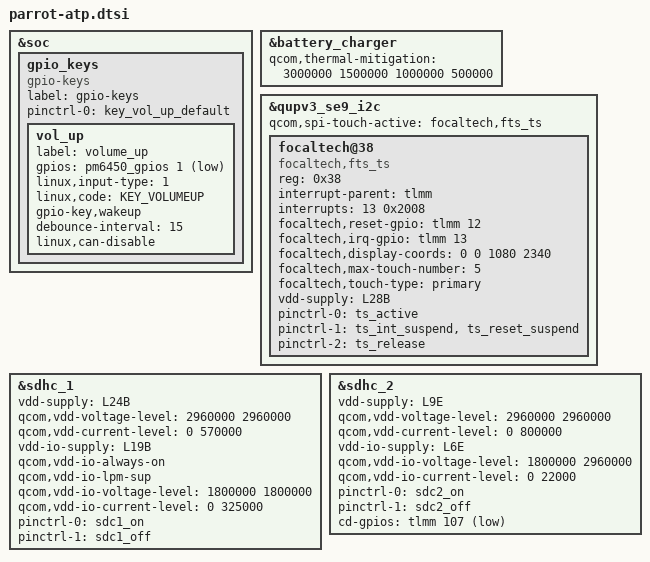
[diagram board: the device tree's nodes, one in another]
#include <dt-bindings/gpio/gpio.h>
#include <dt-bindings/input/input.h>

#include "parrot-pm7250b.dtsi"
#include "parrot-pmic-overlay.dtsi"
#include "parrot-thermal-overlay.dtsi"

&soc {
	gpio_keys {
		compatible = "gpio-keys";
		label = "gpio-keys";

		pinctrl-names = "default";
		pinctrl-0 = <&key_vol_up_default>;

		vol_up {
			label = "volume_up";
			gpios = <&pm6450_gpios 1 GPIO_ACTIVE_LOW>;
			linux,input-type = <1>;
			linux,code = <KEY_VOLUMEUP>;
			gpio-key,wakeup;
			debounce-interval = <15>;
			linux,can-disable;
		};
	};
};

&battery_charger {
	qcom,thermal-mitigation = <3000000 1500000 1000000 500000>;
};

&qupv3_se9_i2c {
	#address-cells = <1>;
	#size-cells = <0>;

	status = "ok";
	qcom,spi-touch-active = "focaltech,fts_ts";

	focaltech@38 {
		compatible = "focaltech,fts_ts";
		reg = <0x38>;
		interrupt-parent = <&tlmm>;
		interrupts = <13 0x2008>;

		focaltech,reset-gpio = <&tlmm 12 0x00>;
		focaltech,irq-gpio = <&tlmm 13 0x2008>;
		focaltech,display-coords = <0 0 1080 2340>;
		focaltech,max-touch-number = <5>;
		focaltech,touch-type = "primary";

		vdd-supply = <&L28B>;

		pinctrl-names = "pmx_ts_active", "pmx_ts_suspend", "pmx_ts_release";
		pinctrl-0 = <&ts_active>;
		pinctrl-1 = <&ts_int_suspend &ts_reset_suspend>;
		pinctrl-2 = <&ts_release>;
	};
};

&sdhc_1 {
	status = "ok";

	vdd-supply = <&L24B>;
	qcom,vdd-voltage-level = <2960000 2960000>;
	qcom,vdd-current-level = <0 570000>;

	vdd-io-supply = <&L19B>;
	qcom,vdd-io-always-on;
	qcom,vdd-io-lpm-sup;
	qcom,vdd-io-voltage-level = <1800000 1800000>;
	qcom,vdd-io-current-level = <0 325000>;

	pinctrl-names = "default", "sleep";
	pinctrl-0 = <&sdc1_on>;
	pinctrl-1 = <&sdc1_off>;
};

&sdhc_2 {
	status = "ok";

	vdd-supply = <&L9E>;
	qcom,vdd-voltage-level = <2960000 2960000>;
	qcom,vdd-current-level = <0 800000>;

	vdd-io-supply = <&L6E>;
	qcom,vdd-io-voltage-level = <1800000 2960000>;
	qcom,vdd-io-current-level = <0 22000>;

	pinctrl-names = "default", "sleep";
	pinctrl-0 = <&sdc2_on>;
	pinctrl-1 = <&sdc2_off>;

	cd-gpios = <&tlmm 107 GPIO_ACTIVE_LOW>;
};
